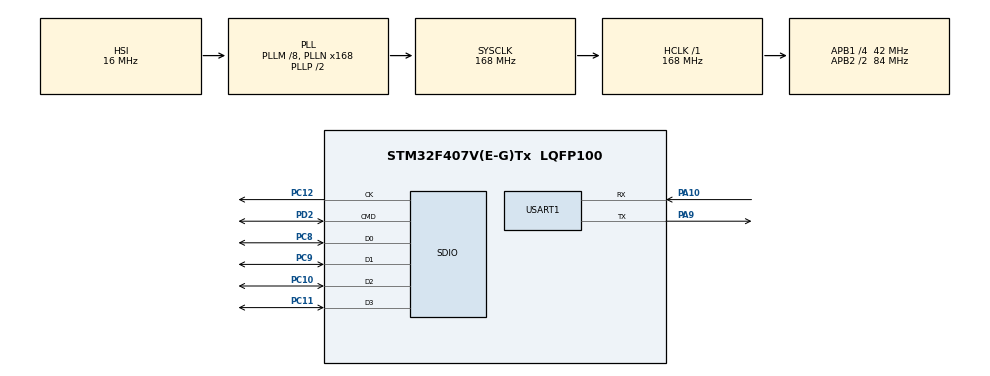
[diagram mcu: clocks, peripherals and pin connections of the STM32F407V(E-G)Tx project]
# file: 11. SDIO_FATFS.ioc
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Dma.Request0=SDIO_TX
Dma.Request1=SDIO_RX
Dma.SDIO_RX.1.Direction=DMA_PERIPH_TO_MEMORY
Dma.SDIO_RX.1.FIFOMode=DMA_FIFOMODE_ENABLE
Dma.SDIO_RX.1.FIFOThreshold=DMA_FIFO_THRESHOLD_FULL
Dma.SDIO_RX.1.Instance=DMA2_Stream6
Dma.SDIO_RX.1.MemBurst=DMA_MBURST_INC4
Dma.SDIO_RX.1.MemDataAlignment=DMA_MDATAALIGN_WORD
Dma.SDIO_RX.1.MemInc=DMA_MINC_ENABLE
Dma.SDIO_RX.1.Mode=DMA_PFCTRL
Dma.SDIO_RX.1.PeriphBurst=DMA_PBURST_INC4
Dma.SDIO_RX.1.PeriphDataAlignment=DMA_PDATAALIGN_WORD
Dma.SDIO_RX.1.PeriphInc=DMA_PINC_DISABLE
Dma.SDIO_RX.1.Priority=DMA_PRIORITY_LOW
Dma.SDIO_TX.0.Direction=DMA_MEMORY_TO_PERIPH
Dma.SDIO_TX.0.FIFOMode=DMA_FIFOMODE_ENABLE
Dma.SDIO_TX.0.FIFOThreshold=DMA_FIFO_THRESHOLD_FULL
Dma.SDIO_TX.0.Instance=DMA2_Stream3
Dma.SDIO_TX.0.MemBurst=DMA_MBURST_INC4
Dma.SDIO_TX.0.MemDataAlignment=DMA_MDATAALIGN_WORD
Dma.SDIO_TX.0.MemInc=DMA_MINC_ENABLE
Dma.SDIO_TX.0.Mode=DMA_PFCTRL
Dma.SDIO_TX.0.PeriphBurst=DMA_PBURST_INC4
Dma.SDIO_TX.0.PeriphDataAlignment=DMA_PDATAALIGN_WORD
Dma.SDIO_TX.0.PeriphInc=DMA_PINC_DISABLE
Dma.SDIO_TX.0.Priority=DMA_PRIORITY_LOW
FATFS.USE_DMA_CODE_SD=1
FATFS._USE_LFN=1
Mcu.Family=STM32F4
Mcu.Name=STM32F407V(E-G)Tx
Mcu.Package=LQFP100
NVIC.DMA2_Stream3_IRQn=true\:0\:0\:false\:false\:true\:false\:true\:true
NVIC.DMA2_Stream6_IRQn=true\:0\:0\:false\:false\:true\:false\:true\:true
NVIC.PriorityGroup=NVIC_PRIORITYGROUP_4
NVIC.SDIO_IRQn=true\:0\:0\:false\:false\:true\:true\:true\:true
PA10.Mode=Asynchronous
PA10.Signal=USART1_RX
PA13.Mode=Serial_Wire
PA13.Signal=SYS_JTMS-SWDIO
PA14.Mode=Serial_Wire
PA14.Signal=SYS_JTCK-SWCLK
PA9.Mode=Asynchronous
PA9.Signal=USART1_TX
PC10.Mode=SD_4_bits_Wide_bus
PC10.Signal=SDIO_D2
PC11.Mode=SD_4_bits_Wide_bus
PC11.Signal=SDIO_D3
PC12.Mode=SD_4_bits_Wide_bus
PC12.Signal=SDIO_CK
PC8.Mode=SD_4_bits_Wide_bus
PC8.Signal=SDIO_D0
PC9.Mode=SD_4_bits_Wide_bus
PC9.Signal=SDIO_D1
PD2.Mode=SD_4_bits_Wide_bus
PD2.Signal=SDIO_CMD
PH0-OSC_IN.Mode=HSE-External-Oscillator
PH0-OSC_IN.Signal=RCC_OSC_IN
PH1-OSC_OUT.Mode=HSE-External-Oscillator
PH1-OSC_OUT.Signal=RCC_OSC_OUT
ProjectManager.HeapSize=0x200
ProjectManager.StackSize=0x400
ProjectManager.TargetToolchain=STM32CubeIDE
RCC.48MHZClocksFreq_Value=48000000
RCC.AHBFreq_Value=168000000
RCC.APB1CLKDivider=RCC_HCLK_DIV4
RCC.APB1Freq_Value=42000000
RCC.APB1TimFreq_Value=84000000
RCC.APB2CLKDivider=RCC_HCLK_DIV2
RCC.APB2Freq_Value=84000000
RCC.APB2TimFreq_Value=168000000
RCC.CortexFreq_Value=168000000
RCC.HCLKFreq_Value=168000000
RCC.HSE_VALUE=25000000
RCC.HSI_VALUE=16000000
RCC.LSE_VALUE=32768
RCC.PLLM=8
RCC.PLLN=168
RCC.PLLQ=7
RCC.SYSCLKFreq_VALUE=168000000
RCC.SYSCLKSource=RCC_SYSCLKSOURCE_PLLCLK
RCC.VCOOutputFreq_Value=336000000
USART1.VirtualMode=VM_ASYNC
VP_FATFS_VS_SDIO.Mode=SDIO
board=custom

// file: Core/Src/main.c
/* USER CODE BEGIN Header */
/**
  ******************************************************************************
  * @file           : main.c
  * @brief          : Main program body
  ******************************************************************************
  * @attention
  *
  * Copyright (c) 2022 STMicroelectronics.
  * All rights reserved.
  *
  * This software is licensed under terms that can be found in the LICENSE file
  * in the root directory of this software component.
  * If no LICENSE file comes with this software, it is provided AS-IS.
  *
  ******************************************************************************
  */
/* USER CODE END Header */
#include "main.h"
#include "dma.h"
#include "fatfs.h"
#include "sdio.h"
#include "usart.h"
#include "gpio.h"

/* USER CODE BEGIN Includes */
#include <stdio.h>
/* USER CODE END Includes */

void SystemClock_Config(void);

int main(void)
{

  /* MCU Configuration--------------------------------------------------------*/

  /* Reset of all peripherals, Initializes the Flash interface and the Systick. */
  HAL_Init();

  /* Configure the system clock */
  SystemClock_Config();

  /* Initialize all configured peripherals */
  MX_GPIO_Init();
  MX_DMA_Init();
  MX_USART1_UART_Init();
  MX_SDIO_SD_Init();
  MX_FATFS_Init();
  /* USER CODE BEGIN 2 */

//  char str[40] = {0};
//  BYTE buf[32] = "Hello world";
//  uint32_t bw, br;

//  if((retSD = f_mount(&SDFatFS, "0:/", 1)) == FR_OK)
//  if((retSD = f_mount(&SDFatFS, &SDPath[0], 1)) == FR_OK)
//  {
//	  sprintf(str, "f_mount OK %d\n", retSD);
//	  HAL_UART_Transmit(&huart1, str, sizeof(str), 10);
//  }
//  else
//  {
//	  sprintf(str, "f_mount Failed %d\n", retSD);
//	  HAL_UART_Transmit(&huart1, str, sizeof(str), 10);
//  }

  /* USER CODE END 2 */

  /* Infinite loop */
  /* USER CODE BEGIN WHILE */
  char str[40] = "Hello World!!\n";
  while (1)
  {
	  HAL_UART_Transmit(&huart1, str, sizeof(str), 100);
	  HAL_Delay(1000);
    /* USER CODE END WHILE */

  }
}

void SystemClock_Config(void)
{
  RCC_OscInitTypeDef RCC_OscInitStruct = {0};
  RCC_ClkInitTypeDef RCC_ClkInitStruct = {0};

  /** Configure the main internal regulator output voltage
  */
  __HAL_RCC_PWR_CLK_ENABLE();
  __HAL_PWR_VOLTAGESCALING_CONFIG(PWR_REGULATOR_VOLTAGE_SCALE1);

  /** Initializes the RCC Oscillators according to the specified parameters
  * in the RCC_OscInitTypeDef structure.
  */
  RCC_OscInitStruct.OscillatorType = RCC_OSCILLATORTYPE_HSI;
  RCC_OscInitStruct.HSIState = RCC_HSI_ON;
  RCC_OscInitStruct.HSICalibrationValue = RCC_HSICALIBRATION_DEFAULT;
  RCC_OscInitStruct.PLL.PLLState = RCC_PLL_ON;
  RCC_OscInitStruct.PLL.PLLSource = RCC_PLLSOURCE_HSI;
  RCC_OscInitStruct.PLL.PLLM = 8;
  RCC_OscInitStruct.PLL.PLLN = 168;
  RCC_OscInitStruct.PLL.PLLP = RCC_PLLP_DIV2;
  RCC_OscInitStruct.PLL.PLLQ = 7;
  if (HAL_RCC_OscConfig(&RCC_OscInitStruct) != HAL_OK)
  {
    Error_Handler();
  }

  /** Initializes the CPU, AHB and APB buses clocks
  */
  RCC_ClkInitStruct.ClockType = RCC_CLOCKTYPE_HCLK|RCC_CLOCKTYPE_SYSCLK
                              |RCC_CLOCKTYPE_PCLK1|RCC_CLOCKTYPE_PCLK2;
  RCC_ClkInitStruct.SYSCLKSource = RCC_SYSCLKSOURCE_PLLCLK;
  RCC_ClkInitStruct.AHBCLKDivider = RCC_SYSCLK_DIV1;
  RCC_ClkInitStruct.APB1CLKDivider = RCC_HCLK_DIV4;
  RCC_ClkInitStruct.APB2CLKDivider = RCC_HCLK_DIV2;

  if (HAL_RCC_ClockConfig(&RCC_ClkInitStruct, FLASH_LATENCY_5) != HAL_OK)
  {
    Error_Handler();
  }
}

void Error_Handler(void)
{
  __disable_irq();
  while (1)
  {
  }
}
